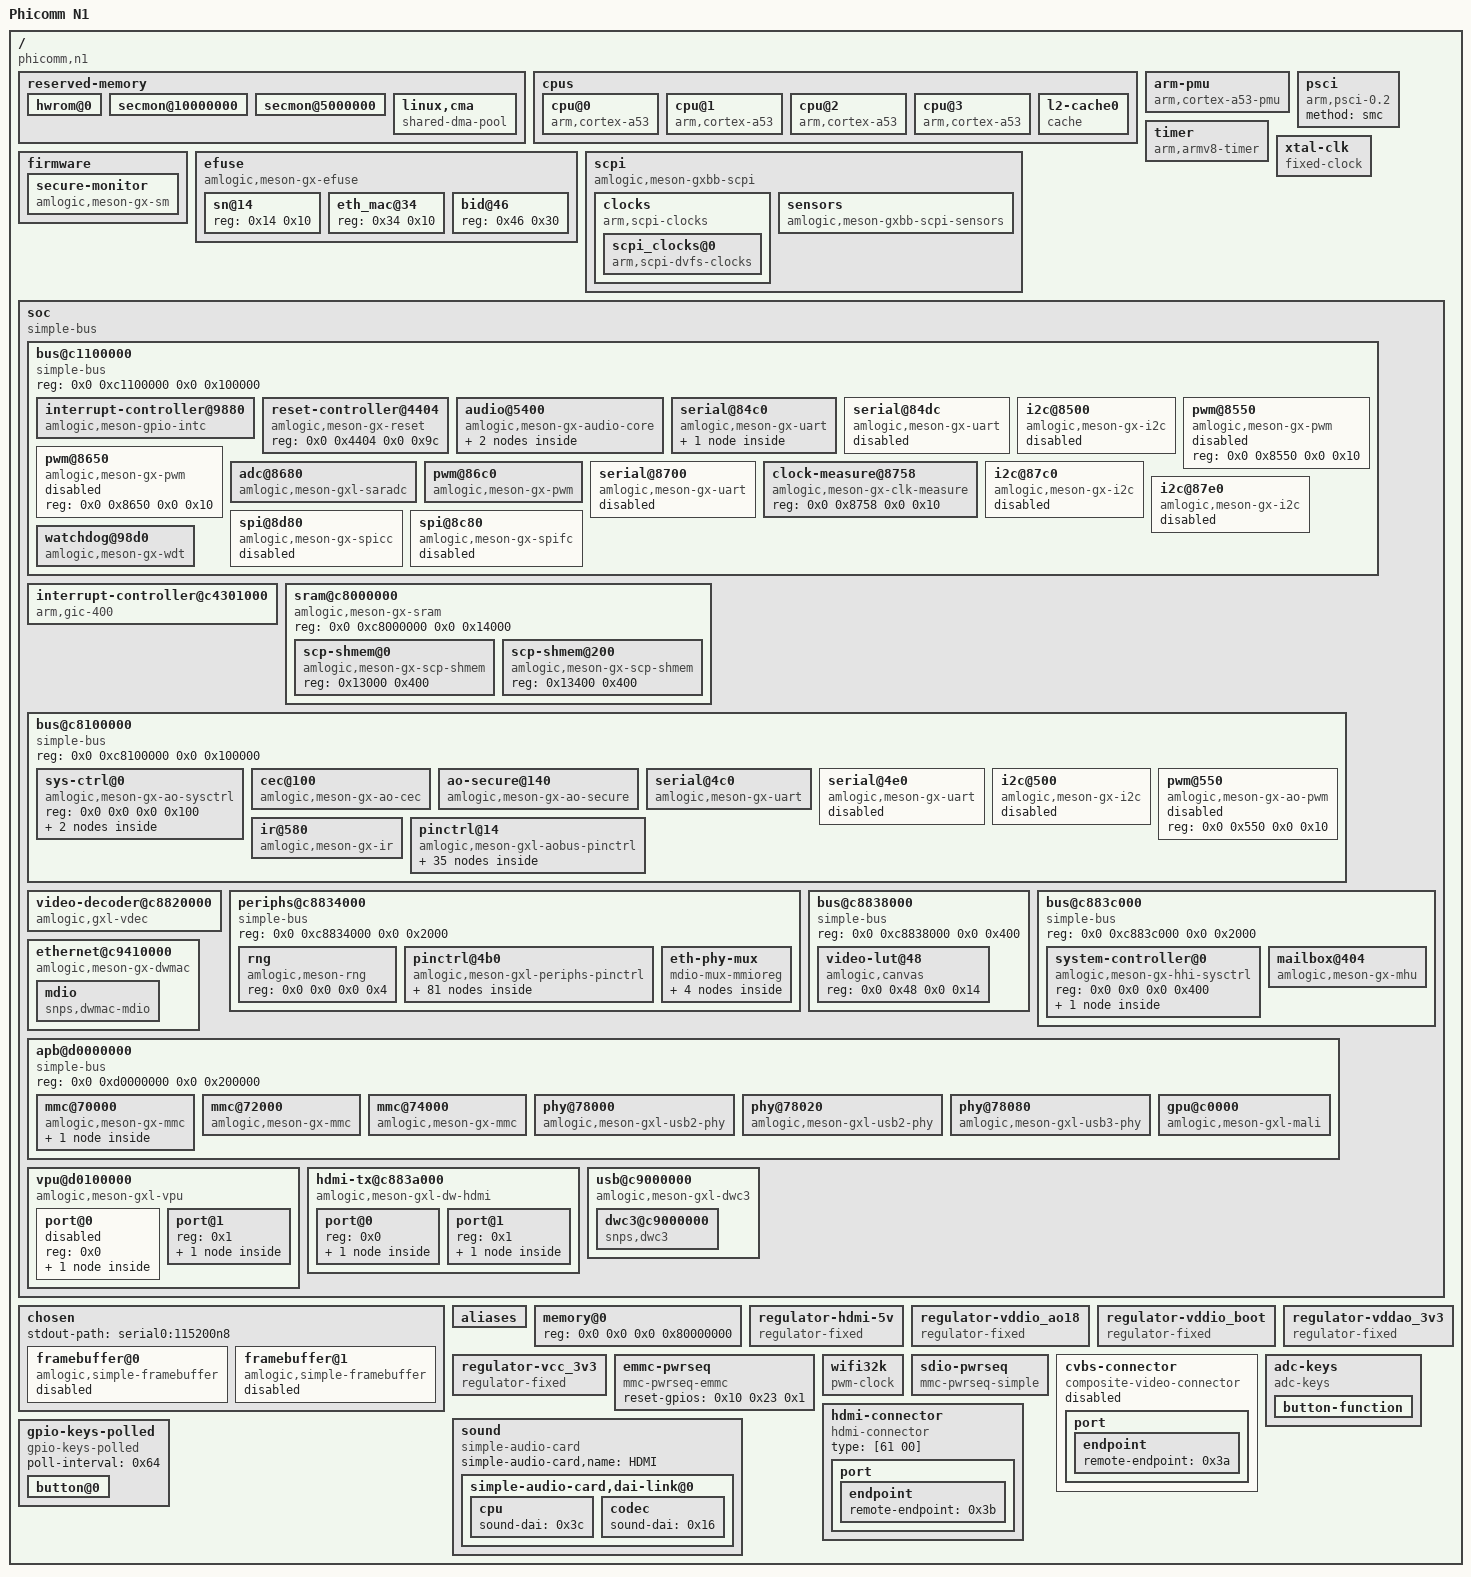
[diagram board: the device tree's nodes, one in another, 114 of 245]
/dts-v1/;

/ {
	interrupt-parent = <0x1>;
	#address-cells = <0x2>;
	#size-cells = <0x2>;
	compatible = "phicomm,n1", "amlogic,s905d", "amlogic,meson-gxl";
	model = "Phicomm N1";

	reserved-memory {
		#address-cells = <0x2>;
		#size-cells = <0x2>;
		ranges;

		hwrom@0 {
			reg = <0x0 0x0 0x0 0x1000000>;
			no-map;
		};

		secmon@10000000 {
			reg = <0x0 0x10000000 0x0 0x200000>;
			no-map;
		};

		secmon@5000000 {
			reg = <0x0 0x5000000 0x0 0x300000>;
			no-map;
		};

		linux,cma {
			compatible = "shared-dma-pool";
			reusable;
			size = <0x0 0x38000000>;
			alignment = <0x0 0x400000>;
			linux,cma-default;
		};
	};

	cpus {
		#address-cells = <0x2>;
		#size-cells = <0x0>;

		cpu@0 {
			device_type = "cpu";
			compatible = "arm,cortex-a53", "arm,armv8";
			reg = <0x0 0x0>;
			enable-method = "psci";
			next-level-cache = <0x2>;
			clocks = <0x3 0x0>;
			phandle = <0x4>;
		};

		cpu@1 {
			device_type = "cpu";
			compatible = "arm,cortex-a53", "arm,armv8";
			reg = <0x0 0x1>;
			enable-method = "psci";
			next-level-cache = <0x2>;
			clocks = <0x3 0x0>;
			phandle = <0x5>;
		};

		cpu@2 {
			device_type = "cpu";
			compatible = "arm,cortex-a53", "arm,armv8";
			reg = <0x0 0x2>;
			enable-method = "psci";
			next-level-cache = <0x2>;
			clocks = <0x3 0x0>;
			phandle = <0x6>;
		};

		cpu@3 {
			device_type = "cpu";
			compatible = "arm,cortex-a53", "arm,armv8";
			reg = <0x0 0x3>;
			enable-method = "psci";
			next-level-cache = <0x2>;
			clocks = <0x3 0x0>;
			phandle = <0x7>;
		};

		l2-cache0 {
			compatible = "cache";
			phandle = <0x2>;
		};
	};

	arm-pmu {
		compatible = "arm,cortex-a53-pmu";
		interrupts = <0x0 0x89 0x4 0x0 0x8a 0x4 0x0 0x99 0x4 0x0 0x9a 0x4>;
		interrupt-affinity = <0x4 0x5 0x6 0x7>;
	};

	psci {
		compatible = "arm,psci-0.2";
		method = "smc";
	};

	timer {
		compatible = "arm,armv8-timer";
		interrupts = <0x1 0xd 0xff08 0x1 0xe 0xff08 0x1 0xb 0xff08 0x1 0xa 0xff08>;
	};

	xtal-clk {
		compatible = "fixed-clock";
		clock-frequency = <0x16e3600>;
		clock-output-names = "xtal";
		#clock-cells = <0x0>;
		phandle = <0xd>;
	};

	firmware {

		secure-monitor {
			compatible = "amlogic,meson-gx-sm", "amlogic,meson-gxbb-sm";
		};
	};

	efuse {
		compatible = "amlogic,meson-gx-efuse", "amlogic,meson-gxbb-efuse";
		#address-cells = <0x1>;
		#size-cells = <0x1>;
		read-only;
		clocks = <0x8 0x3a>;

		sn@14 {
			reg = <0x14 0x10>;
		};

		eth_mac@34 {
			reg = <0x34 0x10>;
		};

		bid@46 {
			reg = <0x46 0x30>;
		};
	};

	scpi {
		compatible = "amlogic,meson-gxbb-scpi", "arm,scpi-pre-1.0";
		mboxes = <0x9 0x1 0x9 0x2>;
		shmem = <0xa 0xb>;

		clocks {
			compatible = "arm,scpi-clocks";

			scpi_clocks@0 {
				compatible = "arm,scpi-dvfs-clocks";
				#clock-cells = <0x1>;
				clock-indices = <0x0>;
				clock-output-names = "vcpu";
				phandle = <0x3>;
			};
		};

		sensors {
			compatible = "amlogic,meson-gxbb-scpi-sensors", "arm,scpi-sensors";
			#thermal-sensor-cells = <0x1>;
		};
	};

	soc {
		compatible = "simple-bus";
		#address-cells = <0x2>;
		#size-cells = <0x2>;
		ranges;

		bus@c1100000 {
			compatible = "simple-bus";
			reg = <0x0 0xc1100000 0x0 0x100000>;
			#address-cells = <0x2>;
			#size-cells = <0x2>;
			ranges = <0x0 0x0 0x0 0xc1100000 0x0 0x100000>;

			interrupt-controller@9880 {
				compatible = "amlogic,meson-gpio-intc", "amlogic,meson-gxl-gpio-intc";
				reg = <0x0 0x9880 0x0 0x10>;
				interrupt-controller;
				#interrupt-cells = <0x2>;
				amlogic,channel-interrupts = <0x40 0x41 0x42 0x43 0x44 0x45 0x46 0x47>;
				status = "okay";
				#phandle = <0x1e>;
			};

			reset-controller@4404 {
				compatible = "amlogic,meson-gx-reset", "amlogic,meson-gxbb-reset";
				reg = <0x0 0x4404 0x0 0x9c>;
				#reset-cells = <0x1>;
				phandle = <0xc>;
			};

			audio@5400 {
				compatible = "amlogic,meson-gx-audio-core";
				reg = <0x0 0x5400 0x0 0x2ac 0x0 0xa000 0x0 0x304>;
				reg-names = "aiu", "audin";
				status = "okay";
				clocks = <0x8 0x2f 0x8 0x26 0x8 0x23>;
				clock-names = "aiu_top", "aiu_glue", "audin";
				resets = <0xc 0x6 0xc 0x41>;
				reset-names = "aiu", "audin";

				audio-controller-0 {
					#sound-dai-cells = <0x0>;
					compatible = "amlogic,meson-aiu-i2s";
					interrupts = <0x0 0x30 0x1>;
					status = "okay";
					clocks = <0x8 0x28 0x8 0x2c 0x8 0x50 0x8 0x6b>;
					clock-names = "fast", "iface", "bclks", "mclk";
					phandle = <0x3c>;
				};

				audio-controller-1 {
					#sound-dai-cells = <0x0>;
					compatible = "amlogic,meson-aiu-spdif";
					interrupts = <0x0 0x32 0x1>;
					status = "disabled";
					clocks = <0x8 0x27 0x8 0x51 0x8 0x6e 0x8 0x6b 0x8 0x71>;
					clock-names = "fast", "iface", "mclk_i958", "mclk_i2s", "mclk";
				};
			};

			serial@84c0 {
				compatible = "amlogic,meson-gx-uart";
				reg = <0x0 0x84c0 0x0 0x18>;
				interrupts = <0x0 0x1a 0x1>;
				status = "okay";
				clocks = <0xd 0x8 0x1a 0xd>;
				clock-names = "xtal", "pclk", "baud";
				pinctrl-0 = <0xe 0xf>;
				pinctrl-names = "default";
				uart-has-rtscts;

				bluetooth {
					compatible = "brcm,bcm43438-bt";
					shutdown-gpios = <0x10 0x60 0x0>;
				};
			};

			serial@84dc {
				compatible = "amlogic,meson-gx-uart";
				reg = <0x0 0x84dc 0x0 0x18>;
				interrupts = <0x0 0x4b 0x1>;
				status = "disabled";
				clocks = <0xd 0x8 0x30 0xd>;
				clock-names = "xtal", "pclk", "baud";
			};

			i2c@8500 {
				compatible = "amlogic,meson-gx-i2c", "amlogic,meson-gxbb-i2c";
				reg = <0x0 0x8500 0x0 0x20>;
				interrupts = <0x0 0x15 0x1>;
				#address-cells = <0x1>;
				#size-cells = <0x0>;
				status = "disabled";
				clocks = <0x8 0x16>;
			};

			pwm@8550 {
				compatible = "amlogic,meson-gx-pwm", "amlogic,meson-gxbb-pwm";
				reg = <0x0 0x8550 0x0 0x10>;
				#pwm-cells = <0x3>;
				status = "disabled";
			};

			pwm@8650 {
				compatible = "amlogic,meson-gx-pwm", "amlogic,meson-gxbb-pwm";
				reg = <0x0 0x8650 0x0 0x10>;
				#pwm-cells = <0x3>;
				status = "disabled";
			};

			adc@8680 {
				compatible = "amlogic,meson-gxl-saradc", "amlogic,meson-saradc";
				reg = <0x0 0x8680 0x0 0x34>;
				#io-channel-cells = <0x1>;
				interrupts = <0x0 0x49 0x1>;
				status = "okay";
				clocks = <0xd 0x8 0x17 0x8 0x61 0x8 0x62>;
				clock-names = "clkin", "core", "adc_clk", "adc_sel";
				vref-supply = <0x11>;
				phandle = <0x3d>;
			};

			pwm@86c0 {
				compatible = "amlogic,meson-gx-pwm", "amlogic,meson-gxbb-pwm";
				reg = <0x0 0x86c0 0x0 0x10>;
				#pwm-cells = <0x3>;
				status = "okay";
				pinctrl-0 = <0x12>;
				pinctrl-names = "default";
				clocks = <0x8 0x6>;
				clock-names = "clkin0";
				phandle = <0x38>;
			};

			serial@8700 {
				compatible = "amlogic,meson-gx-uart";
				reg = <0x0 0x8700 0x0 0x18>;
				interrupts = <0x0 0x5d 0x1>;
				status = "disabled";
				clocks = <0xd 0x8 0x44 0xd>;
				clock-names = "xtal", "pclk", "baud";
			};

			clock-measure@8758 {
				compatible = "amlogic,meson-gx-clk-measure";
				reg = <0x0 0x8758 0x0 0x10>;
			};

			i2c@87c0 {
				compatible = "amlogic,meson-gx-i2c", "amlogic,meson-gxbb-i2c";
				reg = <0x0 0x87c0 0x0 0x20>;
				interrupts = <0x0 0xd6 0x1>;
				#address-cells = <0x1>;
				#size-cells = <0x0>;
				status = "disabled";
				clocks = <0x8 0x16>;
			};

			i2c@87e0 {
				compatible = "amlogic,meson-gx-i2c", "amlogic,meson-gxbb-i2c";
				reg = <0x0 0x87e0 0x0 0x20>;
				interrupts = <0x0 0xd7 0x1>;
				#address-cells = <0x1>;
				#size-cells = <0x0>;
				status = "disabled";
				clocks = <0x8 0x16>;
			};

			spi@8d80 {
				compatible = "amlogic,meson-gx-spicc";
				reg = <0x0 0x8d80 0x0 0x80>;
				interrupts = <0x0 0x51 0x4>;
				#address-cells = <0x1>;
				#size-cells = <0x0>;
				status = "disabled";
				clocks = <0x8 0x15>;
				clock-names = "core";
				resets = <0xc 0xc1>;
				num-cs = <0x1>;
			};

			spi@8c80 {
				compatible = "amlogic,meson-gx-spifc", "amlogic,meson-gxbb-spifc";
				reg = <0x0 0x8c80 0x0 0x80>;
				#address-cells = <0x1>;
				#size-cells = <0x0>;
				status = "disabled";
				clocks = <0x8 0x22>;
			};

			watchdog@98d0 {
				compatible = "amlogic,meson-gx-wdt", "amlogic,meson-gxbb-wdt";
				reg = <0x0 0x98d0 0x0 0x10>;
				clocks = <0xd>;
			};
		};

		interrupt-controller@c4301000 {
			compatible = "arm,gic-400";
			reg = <0x0 0xc4301000 0x0 0x1000 0x0 0xc4302000 0x0 0x2000 0x0 0xc4304000 0x0 0x2000 0x0 0xc4306000 0x0 0x2000>;
			interrupt-controller;
			interrupts = <0x1 0x9 0xff04>;
			#interrupt-cells = <0x3>;
			#address-cells = <0x0>;
			phandle = <0x1>;
		};

		sram@c8000000 {
			compatible = "amlogic,meson-gx-sram", "amlogic,meson-gxbb-sram", "mmio-sram";
			reg = <0x0 0xc8000000 0x0 0x14000>;
			#address-cells = <0x1>;
			#size-cells = <0x1>;
			ranges = <0x0 0x0 0xc8000000 0x14000>;

			scp-shmem@0 {
				compatible = "amlogic,meson-gx-scp-shmem", "amlogic,meson-gxbb-scp-shmem";
				reg = <0x13000 0x400>;
				phandle = <0xa>;
			};

			scp-shmem@200 {
				compatible = "amlogic,meson-gx-scp-shmem", "amlogic,meson-gxbb-scp-shmem";
				reg = <0x13400 0x400>;
				phandle = <0xb>;
			};
		};

		bus@c8100000 {
			compatible = "simple-bus";
			reg = <0x0 0xc8100000 0x0 0x100000>;
			#address-cells = <0x2>;
			#size-cells = <0x2>;
			ranges = <0x0 0x0 0x0 0xc8100000 0x0 0x100000>;

			sys-ctrl@0 {
				compatible = "amlogic,meson-gx-ao-sysctrl", "simple-mfd", "syscon";
				reg = <0x0 0x0 0x0 0x100>;
				phandle = <0x1a>;

				power-controller-vpu {
					compatible = "amlogic,meson-gx-pwrc-vpu";
					#power-domain-cells = <0x0>;
					amlogic,hhi-sysctrl = <0x13>;
					resets = <0xc 0x5 0xc 0xa 0xc 0xd 0xc 0x25 0xc 0x84 0xc 0x85 0xc 0x86 0xc 0x87 0xc 0x89 0xc 0x8c 0xc 0x8d 0xc 0xe7>;
					clocks = <0x8 0x84 0x8 0x8c>;
					clock-names = "vpu", "vapb";
					assigned-clocks = <0x8 0x7e 0x8 0x80 0x8 0x84 0x8 0x85 0x8 0x87 0x8 0x8b>;
					assigned-clock-parents = <0x8 0x5 0x0 0x8 0x80 0x8 0x6 0x0 0x8 0x87>;
					assigned-clock-rates = <0x0 0x27bc86aa 0x0 0x0 0xee6b280 0x0>;
					phandle = <0x2d>;
				};

				clock-controller {
					compatible = "amlogic,meson-gxl-aoclkc", "amlogic,meson-gx-aoclkc";
					#clock-cells = <0x1>;
					#reset-cells = <0x1>;
					clocks = <0xd 0x8 0xc>;
					clock-names = "xtal", "mpeg-clk";
					phandle = <0x14>;
				};
			};

			cec@100 {
				compatible = "amlogic,meson-gx-ao-cec";
				reg = <0x0 0x100 0x0 0x14>;
				interrupts = <0x0 0xc7 0x1>;
				clocks = <0x14 0x6>;
				clock-names = "core";
				status = "okay";
				pinctrl-0 = <0x15>;
				pinctrl-names = "default";
				hdmi-phandle = <0x16>;
			};

			ao-secure@140 {
				compatible = "amlogic,meson-gx-ao-secure", "syscon";
				reg = <0x0 0x140 0x0 0x140>;
				amlogic,has-chip-id;
			};

			serial@4c0 {
				compatible = "amlogic,meson-gx-uart", "amlogic,meson-ao-uart";
				reg = <0x0 0x4c0 0x0 0x18>;
				interrupts = <0x0 0xc1 0x1>;
				status = "okay";
				clocks = <0xd 0x14 0x3 0xd>;
				clock-names = "xtal", "pclk", "baud";
				pinctrl-0 = <0x17>;
				pinctrl-names = "default";
			};

			serial@4e0 {
				compatible = "amlogic,meson-gx-uart", "amlogic,meson-ao-uart";
				reg = <0x0 0x4e0 0x0 0x18>;
				interrupts = <0x0 0xc5 0x1>;
				status = "disabled";
				clocks = <0xd 0x14 0x4 0xd>;
				clock-names = "xtal", "pclk", "baud";
			};

			i2c@500 {
				compatible = "amlogic,meson-gx-i2c", "amlogic,meson-gxbb-i2c";
				reg = <0x0 0x500 0x0 0x20>;
				interrupts = <0x0 0xc3 0x1>;
				#address-cells = <0x1>;
				#size-cells = <0x0>;
				status = "disabled";
				clocks = <0x8 0x5d>;
			};

			pwm@550 {
				compatible = "amlogic,meson-gx-ao-pwm", "amlogic,meson-gxbb-ao-pwm";
				reg = <0x0 0x550 0x0 0x10>;
				#pwm-cells = <0x3>;
				status = "disabled";
			};

			ir@580 {
				compatible = "amlogic,meson-gx-ir", "amlogic,meson-gxbb-ir";
				reg = <0x0 0x580 0x0 0x40>;
				interrupts = <0x0 0xc4 0x1>;
				status = "okay";
				pinctrl-0 = <0x18>;
				pinctrl-names = "default";
				linux,rc-map-name = "rc-geekbox";
			};

			pinctrl@14 {
				compatible = "amlogic,meson-gxl-aobus-pinctrl";
				#address-cells = <0x2>;
				#size-cells = <0x2>;
				ranges;
				phandle = <0x19>;

				bank@14 {
					reg = <0x0 0x14 0x0 0x8 0x0 0x2c 0x0 0x4 0x0 0x24 0x0 0x8>;
					reg-names = "mux", "pull", "gpio";
					gpio-controller;
					#gpio-cells = <0x2>;
					gpio-ranges = <0x19 0x0 0x0 0xe>;
					phandle = <0x3e>;
				};

				uart_ao_a {
					phandle = <0x17>;

					mux {
						groups = "uart_tx_ao_a", "uart_rx_ao_a";
						function = "uart_ao";
						bias-disable;
					};
				};

				uart_ao_a_cts_rts {

					mux {
						groups = "uart_cts_ao_a", "uart_rts_ao_a";
						function = "uart_ao";
						bias-disable;
					};
				};

				uart_ao_b {

					mux {
						groups = "uart_tx_ao_b", "uart_rx_ao_b";
						function = "uart_ao_b";
						bias-disable;
					};
				};

				uart_ao_b_0_1 {

					mux {
						groups = "uart_tx_ao_b_0", "uart_rx_ao_b_1";
						function = "uart_ao_b";
						bias-disable;
					};
				};

				uart_ao_b_cts_rts {

					mux {
						groups = "uart_cts_ao_b", "uart_rts_ao_b";
						function = "uart_ao_b";
						bias-disable;
					};
				};

				remote_input_ao {
					phandle = <0x18>;

					mux {
						groups = "remote_input_ao";
						function = "remote_input_ao";
						bias-disable;
					};
				};

				i2c_ao {

					mux {
						groups = "i2c_sck_ao", "i2c_sda_ao";
						function = "i2c_ao";
						bias-disable;
					};
				};

				pwm_ao_a_3 {

					mux {
						groups = "pwm_ao_a_3";
						function = "pwm_ao_a";
						bias-disable;
					};
				};

				pwm_ao_a_8 {

					mux {
						groups = "pwm_ao_a_8";
						function = "pwm_ao_a";
						bias-disable;
					};
				};

				pwm_ao_b {

					mux {
						groups = "pwm_ao_b";
						function = "pwm_ao_b";
						bias-disable;
					};
				};

				pwm_ao_b_6 {

					mux {
						groups = "pwm_ao_b_6";
						function = "pwm_ao_b";
						bias-disable;
					};
				};

				i2s_out_ch23_ao {

					mux {
						groups = "i2s_out_ch23_ao";
						function = "i2s_out_ao";
						bias-disable;
					};
				};

				i2s_out_ch45_ao {

					mux {
						groups = "i2s_out_ch45_ao";
						function = "i2s_out_ao";
						bias-disable;
					};
				};

				spdif_out_ao_6 {

					mux {
						groups = "spdif_out_ao_6";
						function = "spdif_out_ao";
						bias-disable;
					};
				};

				spdif_out_ao_9 {

					mux {
						groups = "spdif_out_ao_9";
						function = "spdif_out_ao";
						bias-disable;
					};
				};

				ao_cec {
					phandle = <0x15>;

					mux {
						groups = "ao_cec";
						function = "cec_ao";
						bias-disable;
					};
				};

				ee_cec {

					mux {
						groups = "ee_cec";
						function = "cec_ao";
						bias-disable;
					};
				};
			};
		};

		video-decoder@c8820000 {
			compatible = "amlogic,gxl-vdec";
			reg = <0x0 0xc8820000 0x0 0x10000 0x0 0xc110a580 0x0 0xe4>;
			reg-names = "dos", "esparser";
			interrupts = <0x0 0x2c 0x1 0x0 0x20 0x1>;
			interrupt-names = "vdec", "esparser";
			amlogic,ao-sysctrl = <0x1a>;
			amlogic,canvas = <0x1b>;
			clocks = <0x8 0x36 0x8 0x11 0x8 0x99 0x8 0x9c>;
			clock-names = "dos_parser", "dos", "vdec_1", "vdec_hevc";
			resets = <0xc 0x28>;
			reset-names = "esparser";
		};

		periphs@c8834000 {
			compatible = "simple-bus";
			reg = <0x0 0xc8834000 0x0 0x2000>;
			#address-cells = <0x2>;
			#size-cells = <0x2>;
			ranges = <0x0 0x0 0x0 0xc8834000 0x0 0x2000>;

			rng {
				compatible = "amlogic,meson-rng";
				reg = <0x0 0x0 0x0 0x4>;
			};

			pinctrl@4b0 {
				compatible = "amlogic,meson-gxl-periphs-pinctrl";
				#address-cells = <0x2>;
				#size-cells = <0x2>;
				ranges;
				phandle = <0x1c>;

				bank@4b0 {
					reg = <0x0 0x4b0 0x0 0x28 0x0 0x4e8 0x0 0x14 0x0 0x520 0x0 0x14 0x0 0x430 0x0 0x40>;
					reg-names = "mux", "pull", "pull-enable", "gpio";
					gpio-controller;
					#gpio-cells = <0x2>;
					gpio-ranges = <0x1c 0x0 0x0 0x64>;
					phandle = <0x10>;
				};

				emmc {
					phandle = <0x28>;

					mux {
						groups = "emmc_nand_d07", "emmc_cmd", "emmc_clk";
						function = "emmc";
						bias-disable;
					};
				};

				emmc-ds {
					phandle = <0x29>;

					mux {
						groups = "emmc_ds";
						function = "emmc";
						bias-disable;
					};
				};

				emmc_clk_gate {
					phandle = <0x2a>;

					mux {
						groups = "BOOT_8";
						function = "gpio_periphs";
						bias-pull-down;
					};
				};

				nor {

					mux {
						groups = "nor_d", "nor_q", "nor_c", "nor_cs";
						function = "nor";
						bias-disable;
					};
				};

				spi-pins {

					mux {
						groups = "spi_miso", "spi_mosi", "spi_sclk";
						function = "spi";
						bias-disable;
					};
				};

				spi-ss0 {

					mux {
						groups = "spi_ss0";
						function = "spi";
						bias-disable;
					};
				};

				sdcard {
					phandle = <0x26>;

					mux {
						groups = "sdcard_d0", "sdcard_d1", "sdcard_d2", "sdcard_d3", "sdcard_cmd", "sdcard_clk";
						function = "sdcard";
						bias-disable;
					};
				};

				sdcard_clk_gate {
					phandle = <0x27>;

					mux {
						groups = "CARD_2";
						function = "gpio_periphs";
						bias-pull-down;
					};
				};

				sdio {
					phandle = <0x21>;

					mux {
						groups = "sdio_d0", "sdio_d1", "sdio_d2", "sdio_d3", "sdio_cmd", "sdio_clk";
						function = "sdio";
						bias-disable;
					};
				};

				sdio_clk_gate {
					phandle = <0x22>;

					mux {
						groups = "GPIOX_4";
						function = "gpio_periphs";
						bias-pull-down;
					};
				};

				sdio_irq {

					mux {
						groups = "sdio_irq";
						function = "sdio";
						bias-disable;
					};
				};

				uart_a {
					phandle = <0xe>;

					mux {
						groups = "uart_tx_a", "uart_rx_a";
						function = "uart_a";
						bias-disable;
					};
				};

				uart_a_cts_rts {
					phandle = <0xf>;

					mux {
						groups = "uart_cts_a", "uart_rts_a";
						function = "uart_a";
						bias-disable;
					};
				};

				uart_b {

					mux {
						groups = "uart_tx_b", "uart_rx_b";
						function = "uart_b";
						bias-disable;
					};
				};

				uart_b_cts_rts {

					mux {
						groups = "uart_cts_b", "uart_rts_b";
						function = "uart_b";
						bias-disable;
					};
				};

				uart_c {

					mux {
						groups = "uart_tx_c", "uart_rx_c";
						function = "uart_c";
						bias-disable;
					};
				};

				uart_c_cts_rts {

					mux {
						groups = "uart_cts_c", "uart_rts_c";
						function = "uart_c";
						bias-disable;
					};
				};

				i2c_a {

					mux {
						groups = "i2c_sck_a", "i2c_sda_a";
						function = "i2c_a";
						bias-disable;
					};
				};

				i2c_b {

					mux {
						groups = "i2c_sck_b", "i2c_sda_b";
						function = "i2c_b";
						bias-disable;
					};
				};

				i2c_c {

					mux {
						groups = "i2c_sck_c", "i2c_sda_c";
						function = "i2c_c";
						bias-disable;
					};
				};

				eth_c {
					phandle = <0x1f>;

					mux {
						groups = "eth_mdio", "eth_mdc", "eth_clk_rx_clk", "eth_rx_dv", "eth_rxd0", "eth_rxd1", "eth_rxd2", "eth_rxd3", "eth_rgmii_tx_clk", "eth_tx_en", "eth_txd0", "eth_txd1", "eth_txd2", "eth_txd3";
						function = "eth";
						bias-disable;
					};
				};

				eth_link_led {

					mux {
						groups = "eth_link_led";
						function = "eth_led";
						bias-disable;
					};
				};

				eth_act_led {

					mux {
						groups = "eth_act_led";
						function = "eth_led";
					};
				};

				pwm_a {

					mux {
						groups = "pwm_a";
						function = "pwm_a";
						bias-disable;
					};
				};

				pwm_b {

					mux {
						groups = "pwm_b";
						function = "pwm_b";
						bias-disable;
					};
				};

				pwm_c {

					mux {
						groups = "pwm_c";
						function = "pwm_c";
						bias-disable;
					};
				};

				pwm_d {

					mux {
						groups = "pwm_d";
						function = "pwm_d";
						bias-disable;
					};
				};

				pwm_e {
					phandle = <0x12>;

					mux {
						groups = "pwm_e";
						function = "pwm_e";
						bias-disable;
					};
				};

				pwm_f_clk {

					mux {
						groups = "pwm_f_clk";
						function = "pwm_f";
						bias-disable;
					};
				};

				pwm_f_x {

					mux {
						groups = "pwm_f_x";
						function = "pwm_f";
						bias-disable;
					};
				};

				hdmi_hpd {
					phandle = <0x30>;

					mux {
						groups = "hdmi_hpd";
						function = "hdmi_hpd";
						bias-disable;
					};
				};

				hdmi_i2c {
					phandle = <0x31>;

					mux {
						groups = "hdmi_sda", "hdmi_scl";
						function = "hdmi_i2c";
						bias-disable;
					};
				};

				i2s_am_clk {

					mux {
						groups = "i2s_am_clk";
						function = "i2s_out";
						bias-disable;
					};
				};

				i2s_out_ao_clk {

					mux {
						groups = "i2s_out_ao_clk";
						function = "i2s_out";
						bias-disable;
					};
				};

				i2s_out_lr_clk {

					mux {
						groups = "i2s_out_lr_clk";
						function = "i2s_out";
						bias-disable;
					};
				};

				i2s_out_ch01 {

					mux {
						groups = "i2s_out_ch01";
						function = "i2s_out";
						bias-disable;
					};
				};

				i2sout_ch23_z {

					mux {
						groups = "i2sout_ch23_z";
						function = "i2s_out";
						bias-disable;
					};
				};

				i2sout_ch45_z {

					mux {
						groups = "i2sout_ch45_z";
						function = "i2s_out";
						bias-disable;
					};
				};

				i2sout_ch67_z {

					mux {
						groups = "i2sout_ch67_z";
						function = "i2s_out";
						bias-disable;
					};
				};

				spdif_out_ao_h {

					mux {
						groups = "spdif_out_h";
						function = "spdif_out";
						bias-disable;
					};
				};
			};

			eth-phy-mux {
				compatible = "mdio-mux-mmioreg", "mdio-mux";
				#address-cells = <0x1>;
				#size-cells = <0x0>;
				reg = <0x0 0x55c 0x0 0x4>;
				mux-mask = <0xffffffff>;
				mdio-parent-bus = <0x1d>;

				mdio@e40908ff {
					reg = <0xe40908ff>;
					#address-cells = <0x1>;
					#size-cells = <0x0>;

					ethernet-phy@8 {
						compatible = "ethernet-phy-id0181.4400", "ethernet-phy-ieee802.3-c22";
						interrupts = <0x0 0x9 0x4>;
						reg = <0x8>;
						max-speed = <0x64>;
					};
				};

				mdio@2009087f {
					reg = <0x2009087f>;
					#address-cells = <0x1>;
					#size-cells = <0x0>;

					ethernet-phy@0 {
						compatible = "ethernet-phy-id001c.c916", "ethernet-phy-ieee802.3-c22";
						reg = <0x0>;
						max-speed = <0x3e8>;
						interrupt-parent = <0x1e>;
						interrupts = <0x1d 0x8>;
						eee-broken-1000t;
						phandle = <0x20>;
					};
				};
			};
		};

		bus@c8838000 {
			compatible = "simple-bus";
			reg = <0x0 0xc8838000 0x0 0x400>;
			#address-cells = <0x2>;
			#size-cells = <0x2>;
			ranges = <0x0 0x0 0x0 0xc8838000 0x0 0x400>;

			video-lut@48 {
				compatible = "amlogic,canvas";
				reg = <0x0 0x48 0x0 0x14>;
				phandle = <0x1b>;
			};
		};

		bus@c883c000 {
			compatible = "simple-bus";
			reg = <0x0 0xc883c000 0x0 0x2000>;
			#address-cells = <0x2>;
			#size-cells = <0x2>;
			ranges = <0x0 0x0 0x0 0xc883c000 0x0 0x2000>;

			system-controller@0 {
				compatible = "amlogic,meson-gx-hhi-sysctrl", "simple-mfd", "syscon";
				reg = <0x0 0x0 0x0 0x400>;
				phandle = <0x13>;

				clock-controller {
					compatible = "amlogic,gxl-clkc";
					#clock-cells = <0x1>;
					clocks = <0xd>;
					clock-names = "xtal";
					phandle = <0x8>;
				};
			};

			mailbox@404 {
				compatible = "amlogic,meson-gx-mhu", "amlogic,meson-gxbb-mhu";
				reg = <0x0 0x404 0x0 0x4c>;
				interrupts = <0x0 0xd0 0x1 0x0 0xd1 0x1 0x0 0xd2 0x1>;
				#mbox-cells = <0x1>;
				phandle = <0x9>;
			};
		};

		ethernet@c9410000 {
			compatible = "amlogic,meson-gx-dwmac", "amlogic,meson-gxbb-dwmac", "snps,dwmac";
			reg = <0x0 0xc9410000 0x0 0x10000 0x0 0xc8834540 0x0 0x4>;
			interrupts = <0x0 0x8 0x4>;
			interrupt-names = "macirq";
			status = "okay";
			clocks = <0x8 0x24 0x8 0x4 0x8 0xf>;
			clock-names = "stmmaceth", "clkin0", "clkin1";
			pinctrl-0 = <0x1f>;
			pinctrl-names = "default";
			phy-handle = <0x20>;
			amlogic,tx-delay-ns = <0x2>;
			snps,reset-gpio = <0x10 0xe 0x0>;
			snps,reset-delays-us = <0x0 0x2710 0xf4240>;
			snps,reset-active-low;
			phy-mode = "rgmii";

			mdio {
				#address-cells = <0x1>;
				#size-cells = <0x0>;
				compatible = "snps,dwmac-mdio";
				phandle = <0x1d>;
			};
		};

		apb@d0000000 {
			compatible = "simple-bus";
			reg = <0x0 0xd0000000 0x0 0x200000>;
			#address-cells = <0x2>;
			#size-cells = <0x2>;
			ranges = <0x0 0x0 0x0 0xd0000000 0x0 0x200000>;

			mmc@70000 {
				compatible = "amlogic,meson-gx-mmc", "amlogic,meson-gxbb-mmc";
				reg = <0x0 0x70000 0x0 0x800>;
				interrupts = <0x0 0xd8 0x1>;
				status = "okay";
				clocks = <0x8 0x5e 0x8 0x77 0x8 0x4>;
				clock-names = "core", "clkin0", "clkin1";
				resets = <0xc 0x2c>;
				pinctrl-0 = <0x21>;
				pinctrl-1 = <0x22>;
				pinctrl-names = "default", "clk-gate";
				#address-cells = <0x1>;
				#size-cells = <0x0>;
				bus-width = <0x4>;
				cap-sd-highspeed;
				max-frequency = <0x5f5e100>;
				non-removable;
				disable-wp;
				mmc-pwrseq = <0x23>;
				vmmc-supply = <0x24>;
				vqmmc-supply = <0x25>;

				wifi@1 {
					reg = <0x1>;
					compatible = "brcm,bcm4329-fmac";
				};
			};

			mmc@72000 {
				compatible = "amlogic,meson-gx-mmc", "amlogic,meson-gxbb-mmc";
				reg = <0x0 0x72000 0x0 0x800>;
				interrupts = <0x0 0xd9 0x1>;
				status = "okay";
				clocks = <0x8 0x5f 0x8 0x7a 0x8 0x4>;
				clock-names = "core", "clkin0", "clkin1";
				resets = <0xc 0x2d>;
				pinctrl-0 = <0x26>;
				pinctrl-1 = <0x27>;
				pinctrl-names = "default", "clk-gate";
				bus-width = <0x4>;
				cap-sd-highspeed;
				max-frequency = <0x5f5e100>;
				disable-wp;
				cd-gpios = <0x10 0x30 0x1>;
				vmmc-supply = <0x24>;
				vqmmc-supply = <0x25>;
			};

			mmc@74000 {
				compatible = "amlogic,meson-gx-mmc", "amlogic,meson-gxbb-mmc";
				reg = <0x0 0x74000 0x0 0x800>;
				interrupts = <0x0 0xda 0x1>;
				status = "okay";
				clocks = <0x8 0x60 0x8 0x7d 0x8 0x4>;
				clock-names = "core", "clkin0", "clkin1";
				resets = <0xc 0x2e>;
				pinctrl-0 = <0x28 0x29>;
				pinctrl-1 = <0x2a>;
				pinctrl-names = "default", "clk-gate";
				bus-width = <0x8>;
				cap-mmc-highspeed;
				max-frequency = <0x5f5e100>;
				non-removable;
				disable-wp;
				mmc-ddr-1_8v;
				mmc-hs200-1_8v;
				mmc-pwrseq = <0x2b>;
				vmmc-supply = <0x2c>;
				vqmmc-supply = <0x25>;
			};

			phy@78000 {
				compatible = "amlogic,meson-gxl-usb2-phy";
				#phy-cells = <0x0>;
				reg = <0x0 0x78000 0x0 0x20>;
				clocks = <0x8 0x37>;
				clock-names = "phy";
				resets = <0xc 0x22>;
				reset-names = "phy";
				status = "okay";
				phandle = <0x36>;
			};

			phy@78020 {
				compatible = "amlogic,meson-gxl-usb2-phy";
				#phy-cells = <0x0>;
				reg = <0x0 0x78020 0x0 0x20>;
				clocks = <0x8 0x37>;
				clock-names = "phy";
				resets = <0xc 0x22>;
				reset-names = "phy";
				status = "okay";
				phandle = <0x37>;
			};

			phy@78080 {
				compatible = "amlogic,meson-gxl-usb3-phy";
				#phy-cells = <0x0>;
				reg = <0x0 0x78080 0x0 0x20>;
				interrupts = <0x0 0x10 0x4>;
				clocks = <0x8 0x37 0x14 0x6>;
				clock-names = "phy", "peripheral";
				resets = <0xc 0x22 0xc 0x22>;
				reset-names = "phy", "peripheral";
				status = "okay";
				phandle = <0x35>;
			};

			gpu@c0000 {
				compatible = "amlogic,meson-gxl-mali", "arm,mali-450";
				reg = <0x0 0xc0000 0x0 0x40000>;
				interrupts = <0x0 0xa0 0x4 0x0 0xa1 0x4 0x0 0xa2 0x4 0x0 0xa3 0x4 0x0 0xa4 0x4 0x0 0xa5 0x4 0x0 0xa6 0x4 0x0 0xa7 0x4 0x0 0xa8 0x4 0x0 0xa9 0x4>;
				interrupt-names = "gp", "gpmmu", "pp", "pmu", "pp0", "ppmmu0", "pp1", "ppmmu1", "pp2", "ppmmu2";
				clocks = <0x8 0xc 0x8 0x6a>;
				clock-names = "bus", "core";
				assigned-clocks = <0x8 0x9 0x8 0x64 0x8 0x66 0x8 0x6a>;
				assigned-clock-parents = <0x0 0x8 0x9 0x0 0x8 0x66>;
				assigned-clock-rates = <0x2c588a00 0x0 0x2c588a00 0x0>;
			};
		};

		vpu@d0100000 {
			compatible = "amlogic,meson-gxl-vpu", "amlogic,meson-gx-vpu";
			reg = <0x0 0xd0100000 0x0 0x100000 0x0 0xc883c000 0x0 0x1000 0x0 0xc8838000 0x0 0x1000>;
			reg-names = "vpu", "hhi", "dmc";
			interrupts = <0x0 0x3 0x1>;
			#address-cells = <0x1>;
			#size-cells = <0x0>;
			amlogic,canvas = <0x1b>;
			power-domains = <0x2d>;

			port@0 {
				reg = <0x0>;
				status = "disabled";

				endpoint {
					remote-endpoint = <0x2e>;
					phandle = <0x3a>;
				};
			};

			port@1 {
				reg = <0x1>;

				endpoint {
					remote-endpoint = <0x2f>;
					phandle = <0x33>;
				};
			};
		};

		hdmi-tx@c883a000 {
			compatible = "amlogic,meson-gxl-dw-hdmi", "amlogic,meson-gx-dw-hdmi";
			reg = <0x0 0xc883a000 0x0 0x1c>;
			interrupts = <0x0 0x39 0x1>;
			#address-cells = <0x1>;
			#size-cells = <0x0>;
			status = "okay";
			resets = <0xc 0x13 0xc 0x4f 0xc 0x42>;
			reset-names = "hdmitx_apb", "hdmitx", "hdmitx_phy";
			clocks = <0x8 0x3f 0x8 0xc 0x8 0x4d>;
			clock-names = "isfr", "iahb", "venci";
			#sound-dai-cells = <0x0>;
			pinctrl-0 = <0x30 0x31>;
			pinctrl-names = "default";
			hdmi-supply = <0x32>;
			phandle = <0x16>;

			port@0 {
				reg = <0x0>;

				endpoint {
					remote-endpoint = <0x33>;
					phandle = <0x2f>;
				};
			};

			port@1 {
				reg = <0x1>;

				endpoint {
					remote-endpoint = <0x34>;
					phandle = <0x3b>;
				};
			};
		};

		usb@c9000000 {
			status = "okay";
			compatible = "amlogic,meson-gxl-dwc3";
			#address-cells = <0x2>;
			#size-cells = <0x2>;
			ranges;
			clocks = <0x8 0x37>;
			clock-names = "usb_general";
			resets = <0xc 0x22>;
			reset-names = "usb_otg";

			dwc3@c9000000 {
				compatible = "snps,dwc3";
				reg = <0x0 0xc9000000 0x0 0x100000>;
				interrupts = <0x0 0x1e 0x4>;
				dr_mode = "host";
				maximum-speed = "high-speed";
				snps,dis_u2_susphy_quirk;
				phys = <0x35 0x36 0x37>;
			};
		};
	};

	chosen {
		#address-cells = <0x2>;
		#size-cells = <0x2>;
		ranges;
		stdout-path = "serial0:115200n8";

		framebuffer@0 {
			compatible = "amlogic,simple-framebuffer", "simple-framebuffer";
			amlogic,pipeline = "vpu-cvbs";
			power-domains = <0x2d>;
			status = "disabled";
		};

		framebuffer@1 {
			compatible = "amlogic,simple-framebuffer", "simple-framebuffer";
			amlogic,pipeline = "vpu-hdmi";
			clocks = <0x8 0x3f 0x8 0xc 0x8 0x4d>;
			power-domains = <0x2d>;
			status = "disabled";
		};
	};

	aliases {
		serial0 = "/soc/bus@c8100000/serial@4c0";
		serial1 = "/soc/bus@c1100000/serial@84c0";
		ethernet0 = "/soc/ethernet@c9410000";
	};

	memory@0 {
		device_type = "memory";
		reg = <0x0 0x0 0x0 0x80000000>;
	};

	regulator-hdmi-5v {
		compatible = "regulator-fixed";
		regulator-name = "HDMI_5V";
		regulator-min-microvolt = <0x4c4b40>;
		regulator-max-microvolt = <0x4c4b40>;
		gpio = <0x10 0x13 0x0>;
		enable-active-high;
		regulator-always-on;
		phandle = <0x32>;
	};

	regulator-vddio_ao18 {
		compatible = "regulator-fixed";
		regulator-name = "VDDIO_AO18";
		regulator-min-microvolt = <0x1b7740>;
		regulator-max-microvolt = <0x1b7740>;
		phandle = <0x11>;
	};

	regulator-vddio_boot {
		compatible = "regulator-fixed";
		regulator-name = "VDDIO_BOOT";
		regulator-min-microvolt = <0x1b7740>;
		regulator-max-microvolt = <0x1b7740>;
		phandle = <0x25>;
	};

	regulator-vddao_3v3 {
		compatible = "regulator-fixed";
		regulator-name = "VDDAO_3V3";
		regulator-min-microvolt = <0x325aa0>;
		regulator-max-microvolt = <0x325aa0>;
		phandle = <0x24>;
	};

	regulator-vcc_3v3 {
		compatible = "regulator-fixed";
		regulator-name = "VCC_3V3";
		regulator-min-microvolt = <0x325aa0>;
		regulator-max-microvolt = <0x325aa0>;
		phandle = <0x2c>;
	};

	emmc-pwrseq {
		compatible = "mmc-pwrseq-emmc";
		reset-gpios = <0x10 0x23 0x1>;
		phandle = <0x2b>;
	};

	wifi32k {
		compatible = "pwm-clock";
		#clock-cells = <0x0>;
		clock-frequency = <0x8000>;
		pwms = <0x38 0x0 0x7736 0x0>;
		phandle = <0x39>;
	};

	sdio-pwrseq {
		compatible = "mmc-pwrseq-simple";
		reset-gpios = <0x10 0x55 0x1>;
		clocks = <0x39>;
		clock-names = "ext_clock";
		phandle = <0x23>;
	};

	cvbs-connector {
		compatible = "composite-video-connector";
		status = "disabled";

		port {

			endpoint {
				remote-endpoint = <0x3a>;
				phandle = <0x2e>;
			};
		};
	};

	hdmi-connector {
		compatible = "hdmi-connector";
		type = [61 00];

		port {

			endpoint {
				remote-endpoint = <0x3b>;
				phandle = <0x34>;
			};
		};
	};

	sound {
		compatible = "simple-audio-card";
		simple-audio-card,name = "HDMI";

		simple-audio-card,dai-link@0 {
			format = "i2s";
			mclk-fs = <0x80>;
			bitclock-master = <0x3c>;
			frame-master = <0x3c>;
			assigned-clocks = <0x8 0xf 0x8 0xd 0x8 0xe>;
			assigned-clock-parents = <0x0 0x0 0x0>;
			assigned-clock-rates = <0x11940000 0x10266000 0x17700000>;

			cpu {
				sound-dai = <0x3c>;
			};

			codec {
				sound-dai = <0x16>;
			};
		};
	};

	adc-keys {
		compatible = "adc-keys";
		io-channels = <0x3d 0x0>;
		io-channel-names = "buttons";
		keyup-threshold-microvolt = <0x1a17b0>;

		button-function {
			label = "Update";
			linux,code = <0x168>;
			press-threshold-microvolt = <0x2710>;
		};
	};

	gpio-keys-polled {
		compatible = "gpio-keys-polled";
		#address-cells = <0x1>;
		#size-cells = <0x0>;
		poll-interval = <0x64>;

		button@0 {
			label = "power";
			linux,code = <0x74>;
			gpios = <0x3e 0x2 0x1>;
		};
	};
};
